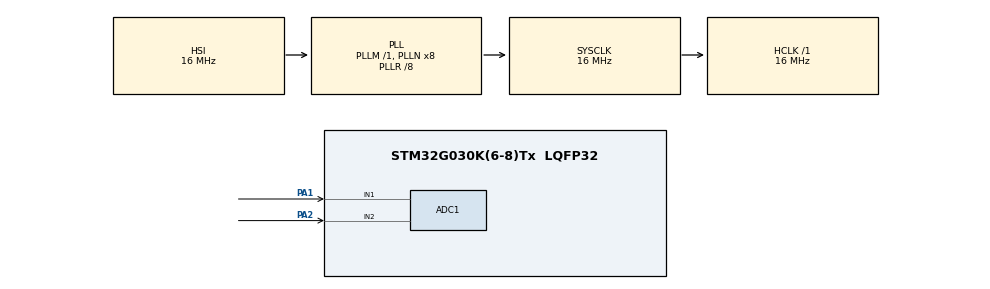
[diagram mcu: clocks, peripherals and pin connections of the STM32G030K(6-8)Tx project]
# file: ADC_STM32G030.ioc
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ADC1.Channel-0\#ChannelRegularConversion=ADC_CHANNEL_1
ADC1.Channel-2\#ChannelRegularConversion=ADC_CHANNEL_2
ADC1.Channel-3\#ChannelRegularConversion=ADC_CHANNEL_VREFINT
ADC1.ClockPrescaler=ADC_CLOCK_ASYNC_DIV1
ADC1.ContinuousConvMode=DISABLE
ADC1.DMAContinuousRequests=ENABLE
ADC1.DiscontinuousConvMode=ENABLE
ADC1.NbrOfConversion=3
ADC1.NbrOfConversionFlag=1
ADC1.Overrun=ADC_OVR_DATA_OVERWRITTEN
ADC1.OversamplingMode=ENABLE
ADC1.Rank-0\#ChannelRegularConversion=1
ADC1.Rank-2\#ChannelRegularConversion=2
ADC1.Rank-3\#ChannelRegularConversion=3
ADC1.Ratio=ADC_OVERSAMPLING_RATIO_4
ADC1.SamplingTime-0\#ChannelRegularConversion=ADC_SAMPLINGTIME_COMMON_1
ADC1.SamplingTime-2\#ChannelRegularConversion=ADC_SAMPLINGTIME_COMMON_1
ADC1.SamplingTime-3\#ChannelRegularConversion=ADC_SAMPLINGTIME_COMMON_1
ADC1.SamplingTimeCommon1=ADC_SAMPLETIME_160CYCLES_5
ADC1.SelectedChannel=ADC_CHANNEL_1|ADC_CHANNEL_2|ADC_CHANNEL_VREFINT
ADC1.master=1
Dma.ADC1.0.Direction=DMA_PERIPH_TO_MEMORY
Dma.ADC1.0.EventEnable=DISABLE
Dma.ADC1.0.Instance=DMA1_Channel1
Dma.ADC1.0.MemDataAlignment=DMA_MDATAALIGN_HALFWORD
Dma.ADC1.0.MemInc=DMA_MINC_ENABLE
Dma.ADC1.0.Mode=DMA_CIRCULAR
Dma.ADC1.0.PeriphDataAlignment=DMA_PDATAALIGN_HALFWORD
Dma.ADC1.0.PeriphInc=DMA_PINC_DISABLE
Dma.ADC1.0.Polarity=HAL_DMAMUX_REQ_GEN_RISING
Dma.ADC1.0.Priority=DMA_PRIORITY_LOW
Dma.ADC1.0.RequestNumber=1
Dma.ADC1.0.SignalID=NONE
Dma.ADC1.0.SyncEnable=DISABLE
Dma.ADC1.0.SyncPolarity=HAL_DMAMUX_SYNC_NO_EVENT
Dma.ADC1.0.SyncRequestNumber=1
Dma.ADC1.0.SyncSignalID=NONE
Dma.Request0=ADC1
Mcu.Family=STM32G0
Mcu.Name=STM32G030K(6-8)Tx
Mcu.Package=LQFP32
NVIC.ADC1_IRQn=true\:0\:0\:false\:false\:true\:true\:true\:true
NVIC.DMA1_Channel1_IRQn=true\:0\:0\:false\:false\:true\:false\:true\:true
PA1.Mode=IN1
PA1.Signal=ADC1_IN1
PA2.Mode=IN2
PA2.Signal=ADC1_IN2
ProjectManager.HeapSize=0x200
ProjectManager.StackSize=0x400
ProjectManager.TargetToolchain=STM32CubeIDE
RCC.ADCCLockSelection=RCC_ADCCLKSOURCE_PLLADC
RCC.ADCFreq_Value=32000000
RCC.AHBFreq_Value=16000000
RCC.CortexFreq_Value=16000000
RCC.EXTERNAL_CLOCK_VALUE=12288000
RCC.HCLKFreq_Value=16000000
RCC.HSE_VALUE=8000000
RCC.HSI_VALUE=16000000
RCC.LSE_VALUE=32768
RCC.PLLP=RCC_PLLP_DIV4
RCC.PLLR=RCC_PLLR_DIV8
RCC.SYSCLKFreq_VALUE=16000000
RCC.SYSCLKSource=RCC_SYSCLKSOURCE_PLLCLK
RCC.VCOOutputFreq_Value=128000000
VP_ADC1_Vref_Input.Mode=IN-Vrefint
board=custom

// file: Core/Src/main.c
/* USER CODE BEGIN Header */
/**
  ******************************************************************************
  * @file           : main.c
  * @brief          : Main program body
  ******************************************************************************
  * @attention
  *
  * Copyright (c) 2025 STMicroelectronics.
  * All rights reserved.
  *
  * This software is licensed under terms that can be found in the LICENSE file
  * in the root directory of this software component.
  * If no LICENSE file comes with this software, it is provided AS-IS.
  *
  ******************************************************************************
  */
/* USER CODE END Header */
#include "main.h"

/* USER CODE BEGIN Includes */
#include "stdio.h"
#include "string.h"
/* USER CODE END Includes */

ADC_HandleTypeDef hadc1;
DMA_HandleTypeDef hdma_adc1;

/* USER CODE BEGIN PV */
#define SAMPLES 255.0f
#define VREFINT_CAL_ADDR   ((uint16_t*)0x1FFF75AA)
#define VREFINT_CAL_VREF   3000UL   // mV
#define NUM_CHANNELS      3
#define OVERSAMPLE_COUNT  64
#define DMA_BUFFER_SIZE   (NUM_CHANNELS * OVERSAMPLE_COUNT)

uint16_t adc_dma_buffer[DMA_BUFFER_SIZE];

float offset_correction;
float gain_correction;
uint32_t sum = 0;
float average = 0.0f;
float corrected_1 = 0;

uint16_t adc_vrefint = 0;   // latest ADC result for VREFINT
uint32_t vdda_mV = 0;       // calculated VDDA (mV)

float voltage = 0.0f;
#define OFFSET_ADC_Volt       3.75f

uint16_t AD_RES_BUFFER[3];
uint16_t adcBuffer[255];

/* USER CODE END PV */

void SystemClock_Config(void);
static void MX_GPIO_Init(void);
static void MX_DMA_Init(void);
static void MX_ADC1_Init(void);

/* USER CODE BEGIN 0 */
void HAL_ADC_ConvCpltCallback(ADC_HandleTypeDef* hadc)
{

}
/* USER CODE END 0 */

int main(void)
{

  /* MCU Configuration--------------------------------------------------------*/

  /* Reset of all peripherals, Initializes the Flash interface and the Systick. */
  HAL_Init();

  /* Configure the system clock */
  SystemClock_Config();

  /* Initialize all configured peripherals */
  MX_GPIO_Init();
  MX_DMA_Init();
  MX_ADC1_Init();
  /* USER CODE BEGIN 2 */
  if (HAL_ADCEx_Calibration_Start(&hadc1) != HAL_OK)
    {
        Error_Handler();
    }

  /* USER CODE END 2 */

  /* Infinite loop */
  while (1)
  {

    /* USER CODE BEGIN 3 */

	  HAL_ADC_Start_DMA(&hadc1, AD_RES_BUFFER, 3UL);

	  sum = 0;

      for (uint16_t i = 0; i < SAMPLES; i++)
      {
     	 HAL_ADC_Start_DMA(&hadc1, AD_RES_BUFFER, 3);
          //adcBuffer[i] = AD_RES_BUFFER[1];   // save each sample in buffer
          sum += AD_RES_BUFFER[1];               // also sum if you still need average
      }

		 average = sum / SAMPLES;

		 corrected_1 = (average > OFFSET_ADC_Volt) ? (average - OFFSET_ADC_Volt) : 0;

		 adc_vrefint = AD_RES_BUFFER[2]; //fixed bandgap reference inside the chip

	     uint16_t vrefint_cal = *VREFINT_CAL_ADDR;

		 vdda_mV = (uint32_t)VREFINT_CAL_VREF * vrefint_cal / adc_vrefint;

		 voltage = (AD_RES_BUFFER[1] * vdda_mV) / 4095 ;

//			 gain_correction = 1.028f;    // Adjust this based on your observed error
//			 offset_correction = 0.07f; // Optional fine offset if needed
//
		 voltage = ( voltage / 50 );

	  HAL_Delay(1);
  }
  /* USER CODE END 3 */
}

void SystemClock_Config(void)
{
  RCC_OscInitTypeDef RCC_OscInitStruct = {0};
  RCC_ClkInitTypeDef RCC_ClkInitStruct = {0};

  /** Configure the main internal regulator output voltage
  */
  HAL_PWREx_ControlVoltageScaling(PWR_REGULATOR_VOLTAGE_SCALE1);

  /** Initializes the RCC Oscillators according to the specified parameters
  * in the RCC_OscInitTypeDef structure.
  */
  RCC_OscInitStruct.OscillatorType = RCC_OSCILLATORTYPE_HSI;
  RCC_OscInitStruct.HSIState = RCC_HSI_ON;
  RCC_OscInitStruct.HSIDiv = RCC_HSI_DIV1;
  RCC_OscInitStruct.HSICalibrationValue = RCC_HSICALIBRATION_DEFAULT;
  RCC_OscInitStruct.PLL.PLLState = RCC_PLL_ON;
  RCC_OscInitStruct.PLL.PLLSource = RCC_PLLSOURCE_HSI;
  RCC_OscInitStruct.PLL.PLLM = RCC_PLLM_DIV1;
  RCC_OscInitStruct.PLL.PLLN = 8;
  RCC_OscInitStruct.PLL.PLLP = RCC_PLLP_DIV4;
  RCC_OscInitStruct.PLL.PLLR = RCC_PLLR_DIV8;
  if (HAL_RCC_OscConfig(&RCC_OscInitStruct) != HAL_OK)
  {
    Error_Handler();
  }

  /** Initializes the CPU, AHB and APB buses clocks
  */
  RCC_ClkInitStruct.ClockType = RCC_CLOCKTYPE_HCLK|RCC_CLOCKTYPE_SYSCLK
                              |RCC_CLOCKTYPE_PCLK1;
  RCC_ClkInitStruct.SYSCLKSource = RCC_SYSCLKSOURCE_PLLCLK;
  RCC_ClkInitStruct.AHBCLKDivider = RCC_SYSCLK_DIV1;
  RCC_ClkInitStruct.APB1CLKDivider = RCC_HCLK_DIV1;

  if (HAL_RCC_ClockConfig(&RCC_ClkInitStruct, FLASH_LATENCY_0) != HAL_OK)
  {
    Error_Handler();
  }
}

static void MX_ADC1_Init(void)
{

  ADC_ChannelConfTypeDef sConfig = {0};

  /** Configure the global features of the ADC (Clock, Resolution, Data Alignment and number of conversion)
  */
  hadc1.Instance = ADC1;
  hadc1.Init.ClockPrescaler = ADC_CLOCK_ASYNC_DIV1;
  hadc1.Init.Resolution = ADC_RESOLUTION_12B;
  hadc1.Init.DataAlign = ADC_DATAALIGN_RIGHT;
  hadc1.Init.ScanConvMode = ADC_SCAN_ENABLE;
  hadc1.Init.EOCSelection = ADC_EOC_SINGLE_CONV;
  hadc1.Init.LowPowerAutoWait = DISABLE;
  hadc1.Init.LowPowerAutoPowerOff = DISABLE;
  hadc1.Init.ContinuousConvMode = DISABLE;
  hadc1.Init.NbrOfConversion = 3;
  hadc1.Init.DiscontinuousConvMode = ENABLE;
  hadc1.Init.ExternalTrigConv = ADC_SOFTWARE_START;
  hadc1.Init.ExternalTrigConvEdge = ADC_EXTERNALTRIGCONVEDGE_NONE;
  hadc1.Init.DMAContinuousRequests = ENABLE;
  hadc1.Init.Overrun = ADC_OVR_DATA_OVERWRITTEN;
  hadc1.Init.SamplingTimeCommon1 = ADC_SAMPLETIME_160CYCLES_5;
  hadc1.Init.SamplingTimeCommon2 = ADC_SAMPLETIME_1CYCLE_5;
  hadc1.Init.OversamplingMode = ENABLE;
  hadc1.Init.Oversampling.Ratio = ADC_OVERSAMPLING_RATIO_4;
  hadc1.Init.Oversampling.RightBitShift = ADC_RIGHTBITSHIFT_NONE;
  hadc1.Init.Oversampling.TriggeredMode = ADC_TRIGGEREDMODE_SINGLE_TRIGGER;
  hadc1.Init.TriggerFrequencyMode = ADC_TRIGGER_FREQ_HIGH;
  if (HAL_ADC_Init(&hadc1) != HAL_OK)
  {
    Error_Handler();
  }

  /** Configure Regular Channel
  */
  sConfig.Channel = ADC_CHANNEL_1;
  sConfig.Rank = ADC_REGULAR_RANK_1;
  sConfig.SamplingTime = ADC_SAMPLINGTIME_COMMON_1;
  if (HAL_ADC_ConfigChannel(&hadc1, &sConfig) != HAL_OK)
  {
    Error_Handler();
  }

  /** Configure Regular Channel
  */
  sConfig.Channel = ADC_CHANNEL_2;
  sConfig.Rank = ADC_REGULAR_RANK_2;
  if (HAL_ADC_ConfigChannel(&hadc1, &sConfig) != HAL_OK)
  {
    Error_Handler();
  }

  /** Configure Regular Channel
  */
  sConfig.Channel = ADC_CHANNEL_VREFINT;
  sConfig.Rank = ADC_REGULAR_RANK_3;
  if (HAL_ADC_ConfigChannel(&hadc1, &sConfig) != HAL_OK)
  {
    Error_Handler();
  }

}

static void MX_DMA_Init(void)
{

  /* DMA controller clock enable */
  __HAL_RCC_DMA1_CLK_ENABLE();

  /* DMA interrupt init */
  /* DMA1_Channel1_IRQn interrupt configuration */
  HAL_NVIC_SetPriority(DMA1_Channel1_IRQn, 0, 0);
  HAL_NVIC_EnableIRQ(DMA1_Channel1_IRQn);

}

static void MX_GPIO_Init(void)
{

  /* GPIO Ports Clock Enable */
  __HAL_RCC_GPIOA_CLK_ENABLE();

}

void Error_Handler(void)
{
  __disable_irq();
  while (1)
  {
  }
}
